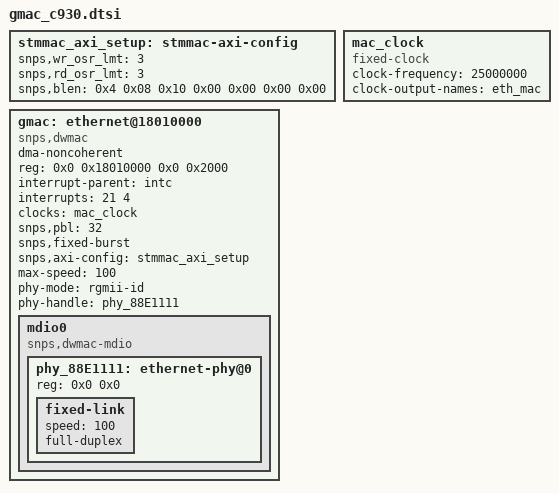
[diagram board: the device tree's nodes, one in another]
        stmmac_axi_setup: stmmac-axi-config{
			snps,wr_osr_lmt = <3>;
			snps,rd_osr_lmt = <3>;
			snps,blen = <0x4 0x08 0x10 0x00 0x00 0x00 0x00> ;
		};
		mac_clock: mac_clock {
			#clock-cells = <0x00>;
			compatible = "fixed-clock";
			clock-frequency = <25000000>;
			clock-output-names = "eth_mac";
		};
		gmac: ethernet@18010000 {
			dma-noncoherent;
			compatible = "snps,dwmac";
			reg = <0x0 0x18010000 0x0 0x2000>;
			interrupt-parent = <&intc>;
			interrupts = <21 4>;
			interrupt-names = "macirq";
			clocks = <&mac_clock>;
			clock-names = "stmmaceth";
			snps,pbl = <32>;
			snps,fixed-burst;
			snps,axi-config = <&stmmac_axi_setup>;
			max-speed = <100>;
			phy-mode = "rgmii-id";
			phy-handle = <&phy_88E1111>;
			mdio0 {
				#address-cells = <1>;
				#size-cells = <0>;
				compatible = "snps,dwmac-mdio";

				phy_88E1111: ethernet-phy@0 {
					reg = <0x0 0x0>;
					fixed-link {
						speed = <100>;
						full-duplex;
					};
				};
			};
		};
